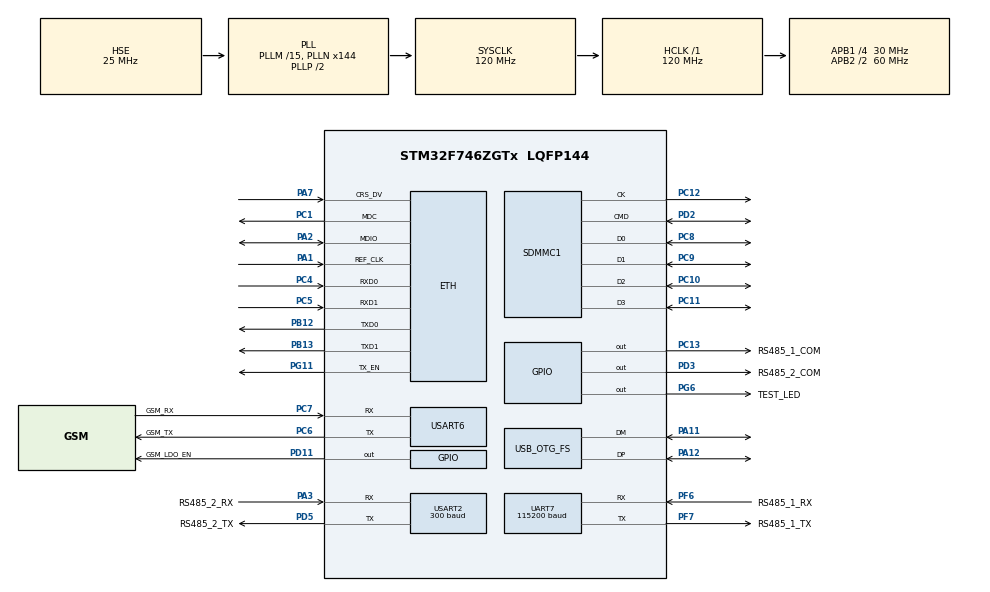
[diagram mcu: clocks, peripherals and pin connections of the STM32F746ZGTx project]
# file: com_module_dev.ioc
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ETH.MediaInterface=ETH_MEDIA_INTERFACE_RMII
FREERTOS.Tasks01=mainTask,0,1280,startMainTask,Default,NULL,Dynamic,NULL,NULL
FREERTOS.configTOTAL_HEAP_SIZE=60000
LWIP.GATEWAY_ADDRESS=192.168.007.001
LWIP.IP_ADDRESS=192.168.007.002
LWIP.LWIP_DHCP=0
LWIP.NETMASK_ADDRESS=255.255.255.000
LWIP.Version=v2.1.2_Cube
Mcu.Family=STM32F7
Mcu.Name=STM32F746ZGTx
Mcu.Package=LQFP144
NVIC.ETH_IRQn=true\:5\:0\:false\:false\:true\:true\:false\:true
NVIC.PriorityGroup=NVIC_PRIORITYGROUP_4
NVIC.TIM1_UP_TIM10_IRQn=true\:0\:0\:false\:false\:true\:false\:false\:true
NVIC.TimeBase=TIM1_UP_TIM10_IRQn
NVIC.TimeBaseIP=TIM1
NVIC.UART7_IRQn=true\:5\:0\:false\:false\:true\:true\:true\:true
NVIC.USART2_IRQn=true\:5\:0\:false\:false\:true\:true\:true\:true
NVIC.USART6_IRQn=true\:5\:0\:false\:false\:true\:true\:true\:true
PA1.Mode=RMII
PA1.Signal=ETH_REF_CLK
PA11.Mode=Device_Only
PA11.Signal=USB_OTG_FS_DM
PA12.Mode=Device_Only
PA12.Signal=USB_OTG_FS_DP
PA13.Mode=JTAG_4_pins
PA13.Signal=SYS_JTMS-SWDIO
PA14.Mode=JTAG_4_pins
PA14.Signal=SYS_JTCK-SWCLK
PA15.Mode=JTAG_4_pins
PA15.Signal=SYS_JTDI
PA2.Mode=RMII
PA2.Signal=ETH_MDIO
PA3.GPIO_Label=RS485_2_RX
PA3.Mode=Asynchronous
PA3.Signal=USART2_RX
PA7.Mode=RMII
PA7.Signal=ETH_CRS_DV
PB12.Mode=RMII
PB12.Signal=ETH_TXD0
PB13.Mode=RMII
PB13.Signal=ETH_TXD1
PB3.Mode=JTAG_4_pins
PB3.Signal=SYS_JTDO-SWO
PC1.Mode=RMII
PC1.Signal=ETH_MDC
PC10.Mode=SD_4_bits_Wide_bus
PC10.Signal=SDMMC1_D2
PC11.Mode=SD_4_bits_Wide_bus
PC11.Signal=SDMMC1_D3
PC12.Mode=SD_4_bits_Wide_bus
PC12.Signal=SDMMC1_CK
PC13.GPIO_Label=RS485_1_COM
PC13.Signal=GPIO_Output
PC4.Mode=RMII
PC4.Signal=ETH_RXD0
PC5.Mode=RMII
PC5.Signal=ETH_RXD1
PC6.GPIO_Label=GSM_TX
PC6.Mode=Asynchronous
PC6.Signal=USART6_TX
PC7.GPIO_Label=GSM_RX
PC7.Mode=Asynchronous
PC7.Signal=USART6_RX
PC8.Mode=SD_4_bits_Wide_bus
PC8.Signal=SDMMC1_D0
PC9.Mode=SD_4_bits_Wide_bus
PC9.Signal=SDMMC1_D1
PD11.GPIO_Label=GSM_LDO_EN
PD11.Signal=GPIO_Output
PD2.Mode=SD_4_bits_Wide_bus
PD2.Signal=SDMMC1_CMD
PD3.GPIO_Label=RS485_2_COM
PD3.Signal=GPIO_Output
PD5.GPIO_Label=RS485_2_TX
PD5.Mode=Asynchronous
PD5.Signal=USART2_TX
PF6.GPIO_Label=RS485_1_RX
PF6.Mode=Asynchronous
PF6.Signal=UART7_RX
PF7.GPIO_Label=RS485_1_TX
PF7.Mode=Asynchronous
PF7.Signal=UART7_TX
PG11.Mode=RMII
PG11.Signal=ETH_TX_EN
PG6.GPIO_Label=TEST_LED
PG6.Signal=GPIO_Output
PH0/OSC_IN.Mode=HSE-External-Oscillator
PH0/OSC_IN.Signal=RCC_OSC_IN
PH1/OSC_OUT.Mode=HSE-External-Oscillator
PH1/OSC_OUT.Signal=RCC_OSC_OUT
ProjectManager.HeapSize=0x200
ProjectManager.StackSize=0x400
ProjectManager.TargetToolchain=STM32CubeIDE
RCC.AHBFreq_Value=120000000
RCC.APB1CLKDivider=RCC_HCLK_DIV4
RCC.APB1Freq_Value=30000000
RCC.APB1TimFreq_Value=60000000
RCC.APB2CLKDivider=RCC_HCLK_DIV2
RCC.APB2Freq_Value=60000000
RCC.APB2TimFreq_Value=120000000
RCC.CortexFreq_Value=120000000
RCC.HCLKFreq_Value=120000000
RCC.HSE_VALUE=25000000
RCC.HSI_VALUE=16000000
RCC.LSE_VALUE=32768
RCC.PLLM=15
RCC.PLLN=144
RCC.PLLQ=5
RCC.SDMMCClockSelection=RCC_SDMMC1CLKSOURCE_CLK48
RCC.SYSCLKFreq_VALUE=120000000
RCC.SYSCLKSource=RCC_SYSCLKSOURCE_PLLCLK
RCC.UART7CLockSelection=RCC_UART7CLKSOURCE_SYSCLK
RCC.USART2CLockSelection=RCC_USART2CLKSOURCE_HSI
RCC.USART6CLockSelection=RCC_USART6CLKSOURCE_HSI
RCC.USBFreq_Value=48000000
RCC.VCOOutputFreq_Value=240000000
UART7.BaudRate=115200
USART2.BaudRate=300
USART2.VirtualMode-Asynchronous=VM_ASYNC
USART6.VirtualMode-Asynchronous=VM_ASYNC
USB_OTG_FS.VirtualMode=Device_Only
VP_FREERTOS_VS_CMSIS_V1.Mode=CMSIS_V1
VP_LWIP_VS_Enabled.Mode=Enabled
VP_SYS_VS_tim1.Mode=TIM1
board=custom

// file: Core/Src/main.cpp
/* USER CODE BEGIN Header */
/**
  ******************************************************************************
  * @file           : main.c
  * @brief          : Main program body
  ******************************************************************************
  * @attention
  *
  * <h2><center>&copy; Copyright (c) 2020 STMicroelectronics.
  * All rights reserved.</center></h2>
  *
  * This software component is licensed by ST under BSD 3-Clause license,
  * the "License"; You may not use this file except in compliance with the
  * License. You may obtain a copy of the License at:
  *                        opensource.org/licenses/BSD-3-Clause
  *
  ******************************************************************************
  */
/* USER CODE END Header */

#include "main.h"
#include "cmsis_os.h"
#include "lwip.h"
#include "sdmmc.h"
#include "usart.h"
#include "usb_otg.h"
#include "gpio.h"

void SystemClock_Config(void);
void MX_FREERTOS_Init(void);

int main(void)
{

  /* MCU Configuration--------------------------------------------------------*/

  /* Reset of all peripherals, Initializes the Flash interface and the Systick. */
  HAL_Init();

  /* Configure the system clock */
  SystemClock_Config();

  /* Initialize all configured peripherals */
  MX_GPIO_Init();
  MX_SDMMC1_SD_Init();
  MX_UART7_Init();
  MX_USART2_UART_Init();
  MX_USART6_UART_Init();
  MX_USB_OTG_FS_PCD_Init();

  /* Call init function for freertos objects (in freertos.c) */
  MX_FREERTOS_Init();
  /* Start scheduler */
  osKernelStart();

  /* We should never get here as control is now taken by the scheduler */
  /* Infinite loop */
  while (1)
  {

  }
}

void SystemClock_Config(void)
{
  RCC_OscInitTypeDef RCC_OscInitStruct = {0};
  RCC_ClkInitTypeDef RCC_ClkInitStruct = {0};
  RCC_PeriphCLKInitTypeDef PeriphClkInitStruct = {0};

  /** Configure the main internal regulator output voltage
  */
  __HAL_RCC_PWR_CLK_ENABLE();
  __HAL_PWR_VOLTAGESCALING_CONFIG(PWR_REGULATOR_VOLTAGE_SCALE3);
  /** Initializes the CPU, AHB and APB busses clocks
  */
  RCC_OscInitStruct.OscillatorType = RCC_OSCILLATORTYPE_HSI|RCC_OSCILLATORTYPE_HSE;
  RCC_OscInitStruct.HSEState = RCC_HSE_ON;
  RCC_OscInitStruct.HSIState = RCC_HSI_ON;
  RCC_OscInitStruct.HSICalibrationValue = RCC_HSICALIBRATION_DEFAULT;
  RCC_OscInitStruct.PLL.PLLState = RCC_PLL_ON;
  RCC_OscInitStruct.PLL.PLLSource = RCC_PLLSOURCE_HSE;
  RCC_OscInitStruct.PLL.PLLM = 15;
  RCC_OscInitStruct.PLL.PLLN = 144;
  RCC_OscInitStruct.PLL.PLLP = RCC_PLLP_DIV2;
  RCC_OscInitStruct.PLL.PLLQ = 5;
  if (HAL_RCC_OscConfig(&RCC_OscInitStruct) != HAL_OK)
  {
    Error_Handler();
  }
  /** Initializes the CPU, AHB and APB busses clocks
  */
  RCC_ClkInitStruct.ClockType = RCC_CLOCKTYPE_HCLK|RCC_CLOCKTYPE_SYSCLK
                              |RCC_CLOCKTYPE_PCLK1|RCC_CLOCKTYPE_PCLK2;
  RCC_ClkInitStruct.SYSCLKSource = RCC_SYSCLKSOURCE_PLLCLK;
  RCC_ClkInitStruct.AHBCLKDivider = RCC_SYSCLK_DIV1;
  RCC_ClkInitStruct.APB1CLKDivider = RCC_HCLK_DIV4;
  RCC_ClkInitStruct.APB2CLKDivider = RCC_HCLK_DIV2;

  if (HAL_RCC_ClockConfig(&RCC_ClkInitStruct, FLASH_LATENCY_3) != HAL_OK)
  {
    Error_Handler();
  }
  PeriphClkInitStruct.PeriphClockSelection = RCC_PERIPHCLK_USART2|RCC_PERIPHCLK_USART6
                              |RCC_PERIPHCLK_UART7|RCC_PERIPHCLK_SDMMC1
                              |RCC_PERIPHCLK_CLK48;
  PeriphClkInitStruct.Usart2ClockSelection = RCC_USART2CLKSOURCE_HSI;
  PeriphClkInitStruct.Usart6ClockSelection = RCC_USART6CLKSOURCE_HSI;
  PeriphClkInitStruct.Uart7ClockSelection = RCC_UART7CLKSOURCE_SYSCLK;
  PeriphClkInitStruct.Clk48ClockSelection = RCC_CLK48SOURCE_PLL;
  PeriphClkInitStruct.Sdmmc1ClockSelection = RCC_SDMMC1CLKSOURCE_CLK48;
  if (HAL_RCCEx_PeriphCLKConfig(&PeriphClkInitStruct) != HAL_OK)
  {
    Error_Handler();
  }
}

 /**
  * @brief  Period elapsed callback in non blocking mode
  * @note   This function is called  when TIM1 interrupt took place, inside
  * HAL_TIM_IRQHandler(). It makes a direct call to HAL_IncTick() to increment
  * a global variable "uwTick" used as application time base.
  * @param  htim : TIM handle
  * @retval None
  */
void HAL_TIM_PeriodElapsedCallback(TIM_HandleTypeDef *htim)
{
  if (htim->Instance == TIM1) {
    HAL_IncTick();
  }
}

void Error_Handler(void)
{
}

/************************ (C) COPYRIGHT STMicroelectronics *****END OF FILE****/

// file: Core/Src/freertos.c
/* USER CODE BEGIN Header */
/**
  ******************************************************************************
  * File Name          : freertos.c
  * Description        : Code for freertos applications
  ******************************************************************************
  * @attention
  *
  * <h2><center>&copy; Copyright (c) 2020 STMicroelectronics.
  * All rights reserved.</center></h2>
  *
  * This software component is licensed by ST under Ultimate Liberty license
  * SLA0044, the "License"; You may not use this file except in compliance with
  * the License. You may obtain a copy of the License at:
  *                             www.st.com/SLA0044
  *
  ******************************************************************************
  */
/* USER CODE END Header */

#include "FreeRTOS.h"
#include "task.h"
#include "main.h"
#include "cmsis_os.h"

osThreadId mainTaskHandle;

void startMainTask(void const * argument);

extern void MX_LWIP_Init(void);

/* GetIdleTaskMemory prototype (linked to static allocation support) */
void vApplicationGetIdleTaskMemory( StaticTask_t **ppxIdleTaskTCBBuffer, StackType_t **ppxIdleTaskStackBuffer, uint32_t *pulIdleTaskStackSize );

/* USER CODE BEGIN GET_IDLE_TASK_MEMORY */
static StaticTask_t xIdleTaskTCBBuffer;
static StackType_t xIdleStack[configMINIMAL_STACK_SIZE];

void vApplicationGetIdleTaskMemory( StaticTask_t **ppxIdleTaskTCBBuffer, StackType_t **ppxIdleTaskStackBuffer, uint32_t *pulIdleTaskStackSize )
{
  *ppxIdleTaskTCBBuffer = &xIdleTaskTCBBuffer;
  *ppxIdleTaskStackBuffer = &xIdleStack[0];
  *pulIdleTaskStackSize = configMINIMAL_STACK_SIZE;
  /* place for user code */
}
/* USER CODE END GET_IDLE_TASK_MEMORY */

void MX_FREERTOS_Init(void) {

  /* Create the thread(s) */
  /* definition and creation of mainTask */
  osThreadDef(mainTask, startMainTask, osPriorityNormal, 0, 1280);
  mainTaskHandle = osThreadCreate(osThread(mainTask), NULL);

}

void startMainTask(void const * argument)
{
	/* init code for LWIP */
	MX_LWIP_Init();
	/* USER CODE BEGIN startMainTask */
	/* Infinite loop */
	for(;;)
	{
		printf("Task is running\n");
		osDelay(1000);
	}
	/* USER CODE END startMainTask */
}

/************************ (C) COPYRIGHT STMicroelectronics *****END OF FILE****/
